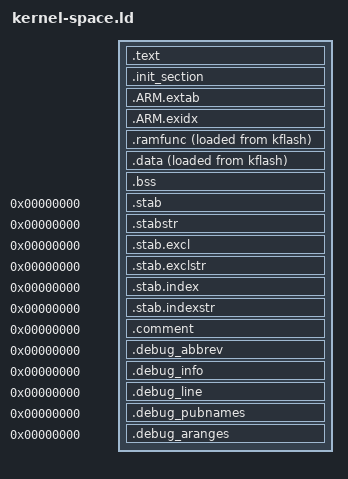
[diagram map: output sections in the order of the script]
/****************************************************************************
 * boards/arm/stm32n6/stm32n6570-dk/scripts/kernel-space.ld
 *
 * SPDX-License-Identifier: Apache-2.0
 *
 ****************************************************************************/

/* NOTE: This depends on memory.ld having been included first. */

OUTPUT_ARCH(arm)
EXTERN(_vectors)
ENTRY(_stext)
SECTIONS
{
    .text :
    {
        _stext = ABSOLUTE(.);
        *(.vectors)
        *(.text .text.*)
        *(.fixup)
        *(.gnu.warning)
        *(.rodata .rodata.*)
        *(.gnu.linkonce.t.*)
        *(.glue_7)
        *(.glue_7t)
        *(.got)
        *(.gcc_except_table)
        *(.gnu.linkonce.r.*)
        _etext = ABSOLUTE(.);
    } > kflash

    .init_section :
    {
        _sinit = ABSOLUTE(.);
        KEEP(*(SORT_BY_INIT_PRIORITY(.init_array.*) SORT_BY_INIT_PRIORITY(.ctors.*)))
        KEEP(*(.init_array EXCLUDE_FILE(*crtbegin.o *crtbegin?.o *crtend.o *crtend?.o) .ctors))
        _einit = ABSOLUTE(.);
    } > kflash

    .ARM.extab :
    {
        *(.ARM.extab*)
    } > kflash

    __exidx_start = ABSOLUTE(.);
    .ARM.exidx :
    {
        *(.ARM.exidx*)
    } > kflash
    __exidx_end = ABSOLUTE(.);

    .ramfunc :
    {
        _sramfuncs = ABSOLUTE(.);
        *(.ramfunc .ramfunc.*)
        . = ALIGN(4);
        _eramfuncs = ABSOLUTE(.);
    } > ksram AT > kflash

    _framfuncs = LOADADDR(.ramfunc);

    .data :
    {
        _sdata = ABSOLUTE(.);
        *(.data .data.*)
        *(.gnu.linkonce.d.*)
        CONSTRUCTORS
        . = ALIGN(4);
        _edata = ABSOLUTE(.);
    } > ksram AT > kflash

    _eronly = LOADADDR(.data);

    .bss :
    {
        _sbss = ABSOLUTE(.);
        *(.bss .bss.*)
        *(.gnu.linkonce.b.*)
        *(COMMON)
        . = ALIGN(8);
        _ebss = ABSOLUTE(.);
    } > ksram

    .stab 0 : { *(.stab) }
    .stabstr 0 : { *(.stabstr) }
    .stab.excl 0 : { *(.stab.excl) }
    .stab.exclstr 0 : { *(.stab.exclstr) }
    .stab.index 0 : { *(.stab.index) }
    .stab.indexstr 0 : { *(.stab.indexstr) }
    .comment 0 : { *(.comment) }
    .debug_abbrev 0 : { *(.debug_abbrev) }
    .debug_info 0 : { *(.debug_info) }
    .debug_line 0 : { *(.debug_line) }
    .debug_pubnames 0 : { *(.debug_pubnames) }
    .debug_aranges 0 : { *(.debug_aranges) }
}
